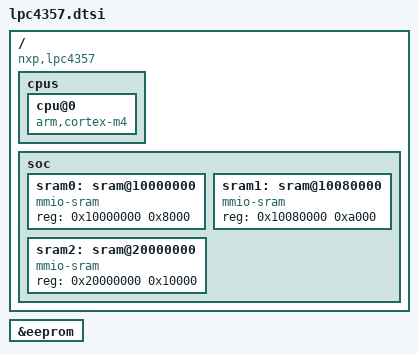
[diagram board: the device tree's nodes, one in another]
/ {
	compatible = "nxp,lpc4357";
	cpus {
		cpu@0 {
			compatible = "arm,cortex-m4";
		};
	};
	soc {
		sram0: sram@10000000 {
			compatible = "mmio-sram";
			reg = <0x10000000 0x8000>;  
		};
		sram1: sram@10080000 {
			compatible = "mmio-sram";
			reg = <0x10080000 0xa000>;  
		};
		sram2: sram@20000000 {
			compatible = "mmio-sram";
			reg = <0x20000000 0x10000>;  
		};
	};
};
&eeprom {
	status = "okay";
};
